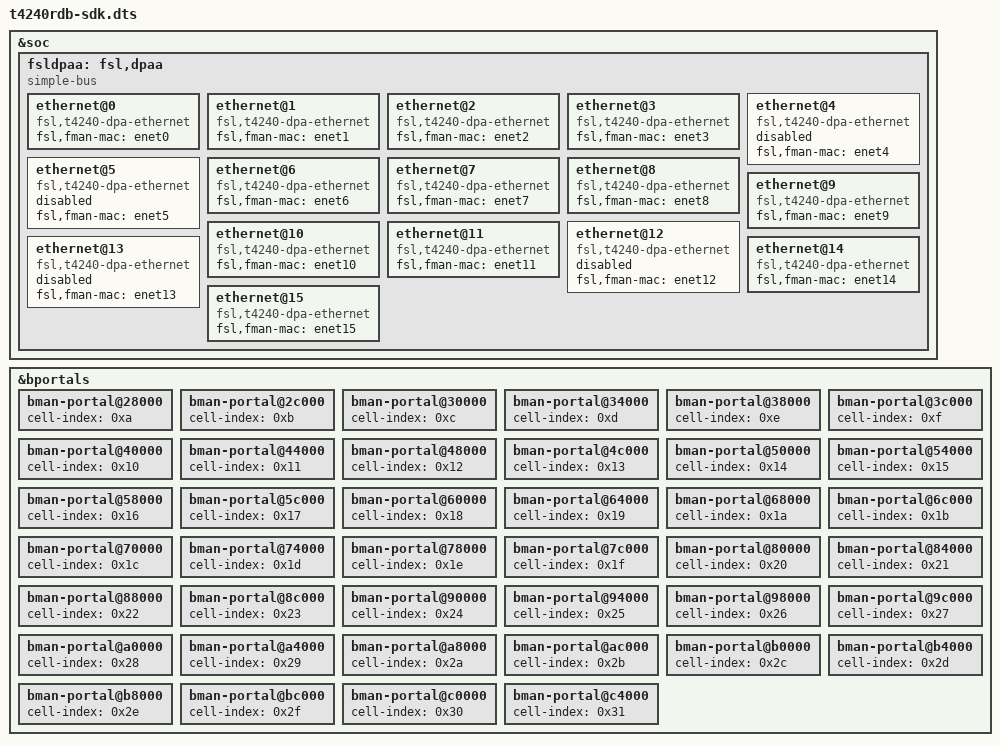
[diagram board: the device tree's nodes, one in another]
// SPDX-License-Identifier: (GPL-2.0+ OR BSD-3-Clause)
/*
 * Copyright 2017-2018 NXP
 */

/include/ "t4240rdb.dts"

/include/ "qoriq-fman3-0-sdk.dtsi"
/include/ "qoriq-fman3-1-sdk.dtsi"
/include/ "qoriq-bman-portals-sdk.dtsi"
/include/ "qoriq-qman3-portals-sdk.dtsi"
/include/ "qoriq-qman3-ceetm0-32-sdk.dtsi"
/include/ "qoriq-qman3-ceetm1-32-sdk.dtsi"

&soc {
	fsldpaa: fsl,dpaa {
		compatible = "simple-bus", "fsl,dpaa";
		ethernet@0 {
			compatible = "fsl,t4240-dpa-ethernet", "fsl,dpa-ethernet";
			fsl,fman-mac = <&enet0>;
		};
		ethernet@1 {
			compatible = "fsl,t4240-dpa-ethernet", "fsl,dpa-ethernet";
			fsl,fman-mac = <&enet1>;
		};
		ethernet@2 {
			compatible = "fsl,t4240-dpa-ethernet", "fsl,dpa-ethernet";
			fsl,fman-mac = <&enet2>;
		};
		ethernet@3 {
			compatible = "fsl,t4240-dpa-ethernet", "fsl,dpa-ethernet";
			fsl,fman-mac = <&enet3>;
		};
		ethernet@4 {
			compatible = "fsl,t4240-dpa-ethernet", "fsl,dpa-ethernet";
			fsl,fman-mac = <&enet4>;
			status = "disabled";
		};
		ethernet@5 {
			compatible = "fsl,t4240-dpa-ethernet", "fsl,dpa-ethernet";
			fsl,fman-mac = <&enet5>;
			status = "disabled";
		};
		ethernet@6 {
			compatible = "fsl,t4240-dpa-ethernet", "fsl,dpa-ethernet";
			fsl,fman-mac = <&enet6>;
		};
		ethernet@7 {
			compatible = "fsl,t4240-dpa-ethernet", "fsl,dpa-ethernet";
			fsl,fman-mac = <&enet7>;
		};
		ethernet@8 {
			compatible = "fsl,t4240-dpa-ethernet", "fsl,dpa-ethernet";
			fsl,fman-mac = <&enet8>;
		};
		ethernet@9 {
			compatible = "fsl,t4240-dpa-ethernet", "fsl,dpa-ethernet";
			fsl,fman-mac = <&enet9>;
		};
		ethernet@10 {
			compatible = "fsl,t4240-dpa-ethernet", "fsl,dpa-ethernet";
			fsl,fman-mac = <&enet10>;
		};
		ethernet@11 {
			compatible = "fsl,t4240-dpa-ethernet", "fsl,dpa-ethernet";
			fsl,fman-mac = <&enet11>;
		};
		ethernet@12 {
			compatible = "fsl,t4240-dpa-ethernet", "fsl,dpa-ethernet";
			fsl,fman-mac = <&enet12>;
			status = "disabled";
		};
		ethernet@13 {
			compatible = "fsl,t4240-dpa-ethernet", "fsl,dpa-ethernet";
			fsl,fman-mac = <&enet13>;
			status = "disabled";
		};
		ethernet@14 {
			compatible = "fsl,t4240-dpa-ethernet", "fsl,dpa-ethernet";
			fsl,fman-mac = <&enet14>;
		};
		ethernet@15 {
			compatible = "fsl,t4240-dpa-ethernet", "fsl,dpa-ethernet";
			fsl,fman-mac = <&enet15>;
		};
	};
};

&bportals {
	bman-portal@28000 {
		cell-index = <0xa>;
	};

	bman-portal@2c000 {
		cell-index = <0xb>;
	};

	bman-portal@30000 {
		cell-index = <0xc>;
	};

	bman-portal@34000 {
		cell-index = <0xd>;
	};

	bman-portal@38000 {
		cell-index = <0xe>;
	};

	bman-portal@3c000 {
		cell-index = <0xf>;
	};

	bman-portal@40000 {
		cell-index = <0x10>;
	};

	bman-portal@44000 {
		cell-index = <0x11>;
	};

	bman-portal@48000 {
		cell-index = <0x12>;
	};

	bman-portal@4c000 {
		cell-index = <0x13>;
	};

	bman-portal@50000 {
		cell-index = <0x14>;
	};

	bman-portal@54000 {
		cell-index = <0x15>;
	};

	bman-portal@58000 {
		cell-index = <0x16>;
	};

	bman-portal@5c000 {
		cell-index = <0x17>;
	};

	bman-portal@60000 {
		cell-index = <0x18>;
	};

	bman-portal@64000 {
		cell-index = <0x19>;
	};

	bman-portal@68000 {
		cell-index = <0x1a>;
	};

	bman-portal@6c000 {
		cell-index = <0x1b>;
	};

	bman-portal@70000 {
		cell-index = <0x1c>;
	};

	bman-portal@74000 {
		cell-index = <0x1d>;
	};

	bman-portal@78000 {
		cell-index = <0x1e>;
	};

	bman-portal@7c000 {
		cell-index = <0x1f>;
	};

	bman-portal@80000 {
		cell-index = <0x20>;
	};

	bman-portal@84000 {
		cell-index = <0x21>;
	};

	bman-portal@88000 {
		cell-index = <0x22>;
	};

	bman-portal@8c000 {
		cell-index = <0x23>;
	};

	bman-portal@90000 {
		cell-index = <0x24>;
	};

	bman-portal@94000 {
		cell-index = <0x25>;
	};

	bman-portal@98000 {
		cell-index = <0x26>;
	};

	bman-portal@9c000 {
		cell-index = <0x27>;
	};

	bman-portal@a0000 {
		cell-index = <0x28>;
	};

	bman-portal@a4000 {
		cell-index = <0x29>;
	};

	bman-portal@a8000 {
		cell-index = <0x2a>;
	};

	bman-portal@ac000 {
		cell-index = <0x2b>;
	};

	bman-portal@b0000 {
		cell-index = <0x2c>;
	};

	bman-portal@b4000 {
		cell-index = <0x2d>;
	};

	bman-portal@b8000 {
		cell-index = <0x2e>;
	};

	bman-portal@bc000 {
		cell-index = <0x2f>;
	};

	bman-portal@c0000 {
		cell-index = <0x30>;
	};

	bman-portal@c4000 {
		cell-index = <0x31>;
	};
};
